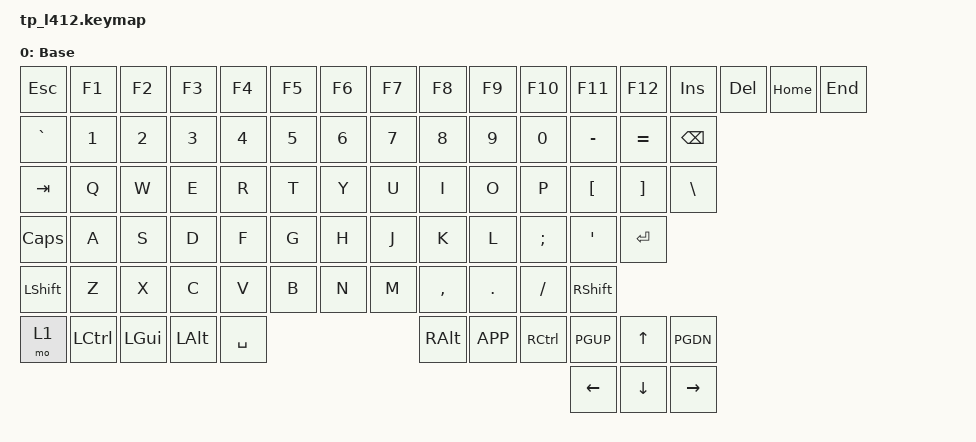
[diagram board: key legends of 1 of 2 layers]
#include <behaviors.dtsi>
#include <dt-bindings/zmk/keys.h>

/ {
    keymap {
        compatible = "zmk,keymap";

// --------------------------------------------------------------------------------------------------
// |  ESC  | F1 | F2 | F3 | F4 | F5 | F6 | F7 | F8 | F9 | F10 | F11 | F12 | INS | DEL | HOME | END  |
// |   `   |  1  |  2  |  3  |  4  |  5  |  6  |  7  |  8  |  9  |  0  |  -  |  =  |     BKSP       |
// |  TAB     |  Q  |  W  |  E  |  R  |  T  |  Y  |  U  |  I  |  O  |  P  |  [  |  ]  |     \       |
// |  LCTRL    |  A  |  S  |  D  |  F  |  G  |  H  |  J  |  K  |  L  |  ;  |  '  |      ENTER       |
// |  SHIFT       |  Z  |  X  |  C  |  V   |  B  |  N  |  M  |  ,  |  .  |  /  |        RSHFT       |
// | FN | LCTRL | LGUI | LALT |             SPACE            | RALT | FN | RCTRL | PGUP | UP | PGDN |
// ------------------------------------------------------------------------------| LEFT | DN | RGHT |
// --------------------------------------------------------------------------------------------------

        default_layer { // Layer 0
            display-name = "Base";
            bindings = <
                &kp ESC   &kp F1    &kp F2   &kp F3   &kp F4    &kp F5 &kp F6 &kp F7 &kp F8    &kp F9  &kp F10   &kp F11   &kp F12   &kp INS  &kp DEL &kp HOME &kp END
                &kp GRAVE &kp N1    &kp N2   &kp N3   &kp N4    &kp N5 &kp N6 &kp N7 &kp N8    &kp N9  &kp N0    &kp MINUS &kp EQUAL &kp BSPC
                &kp TAB   &kp Q     &kp W    &kp E    &kp R     &kp T  &kp Y  &kp U  &kp I     &kp O   &kp P     &kp LBKT  &kp RBKT  &kp BSLH
                &kp CAPS  &kp A     &kp S    &kp D    &kp F     &kp G  &kp H  &kp J  &kp K     &kp L   &kp SEMI  &kp SQT   &kp RET
                &kp LSHFT &kp Z     &kp X    &kp C    &kp V     &kp B  &kp N  &kp M  &kp COMMA &kp DOT &kp SLASH &kp RSHFT 
                &mo 1     &kp LCTRL &kp LGUI &kp LALT &kp SPACE                      &kp RALT  &kp K_APP   &kp RCTRL &kp PGUP  &kp UP    &kp PGDN
                                                                                                                 &kp LEFT  &kp DOWN  &kp RIGHT
            >;
        };

// --------------------------------------------------------------------------------------------------
// |  ESC  | F1 | F2 | F3 | F4 | F5 | F6 | F7 | F8 | F9 | F10 | F11 | F12 | INS | DEL | HOME | END  |
// |   `   |  1  |  2  |  3  |  4  |  5  |  6  |  7  |  8  |  9  |  0  |  -  |  =  |     BKSP       |
// |  TAB     |  Q  |  W  |  E  |  R  |  T  |  Y  |  U  |  I  |  O  |  P  |  [  |  ]  |     \       |
// |  LCTRL    |  A  |  S  |  D  |  F  |  G  |  H  |  J  |  K  |  L  |  ;  |  '  |      ENTER       |
// |  SHIFT       |  Z  |  X  |  C  |  V   |  B  |  N  |  M  |  ,  |  .  |  /  |        RSHFT       |
// | FN | LCTRL | LGUI | LALT |             SPACE            | RALT | FN | RCTRL | PGUP | UP | PGDN |
// ------------------------------------------------------------------------------| LEFT | DN | RGHT |
// --------------------------------------------------------------------------------------------------

        function_layer { // Layer 1
            display-name = "Function";
            bindings = <
                &trans &trans &trans &trans &trans &trans &trans &trans &trans     &kp SLCK   &kp KP_NUM &kp PAUSE_BREAK &trans &kp PSCRN &kp C_BRI_UP &kp C_BRI_DN &studio_unlock
                &trans &trans &trans &trans &trans &trans &trans &trans &trans     &trans     &trans     &trans          &trans &trans
                &trans &trans &trans &trans &trans &trans &trans &trans &trans     &trans     &trans     &trans          &trans &trans
                &trans &trans &trans &trans &trans &trans &trans &trans &trans     &trans     &trans     &trans          &trans
                &trans &trans &trans &trans &trans &trans &trans &trans &trans     &kp C_STOP &trans         
                                                                        &kp C_PREV &kp C_PP   &kp C_NEXT
            >;
        };

        extra1 {
            status = "reserved";
        };

        extra2 {
            status = "reserved";
        };
    };
 };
